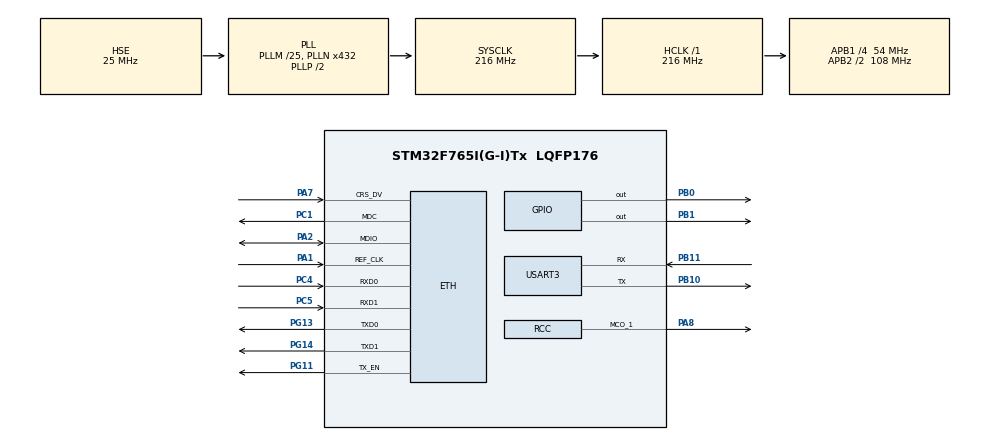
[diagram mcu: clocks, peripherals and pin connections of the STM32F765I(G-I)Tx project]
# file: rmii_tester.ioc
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ETH.MediaInterface=HAL_ETH_RMII_MODE
LWIP.BSP.number=1
LWIP.Version=v2.1.2_Cube
LWIP0.BSP.STBoard=false
LWIP0.BSP.api=BSP_COMPONENT_DRIVER
LWIP0.BSP.component=LAN8742
LWIP0.BSP.instance=LAN8742
LWIP0.BSP.name=Driver_PHY
LWIP0.BSP.semaphore=S_LAN8742
LWIP0.BSP.solution=LAN8742
Mcu.Family=STM32F7
Mcu.Name=STM32F765I(G-I)Tx
Mcu.Package=LQFP176
NVIC.PriorityGroup=NVIC_PRIORITYGROUP_4
PA1.Mode=RMII
PA1.Signal=ETH_REF_CLK
PA2.Mode=RMII
PA2.Signal=ETH_MDIO
PA7.Mode=RMII
PA7.Signal=ETH_CRS_DV
PA8.Mode=Clock-out-1
PA8.Signal=RCC_MCO_1
PB0.Signal=GPIO_Output
PB1.Signal=GPIO_Output
PB10.Mode=Asynchronous
PB10.Signal=USART3_TX
PB11.Mode=Asynchronous
PB11.Signal=USART3_RX
PC1.Mode=RMII
PC1.Signal=ETH_MDC
PC4.Mode=RMII
PC4.Signal=ETH_RXD0
PC5.Mode=RMII
PC5.Signal=ETH_RXD1
PG11.Mode=RMII
PG11.Signal=ETH_TX_EN
PG13.Mode=RMII
PG13.Signal=ETH_TXD0
PG14.Mode=RMII
PG14.Signal=ETH_TXD1
PH0/OSC_IN.Mode=HSE-External-Oscillator
PH0/OSC_IN.Signal=RCC_OSC_IN
PH1/OSC_OUT.Mode=HSE-External-Oscillator
PH1/OSC_OUT.Signal=RCC_OSC_OUT
ProjectManager.HeapSize=0x200
ProjectManager.StackSize=0x400
ProjectManager.TargetToolchain=Makefile
RCC.AHBFreq_Value=216000000
RCC.APB1CLKDivider=RCC_HCLK_DIV4
RCC.APB1Freq_Value=54000000
RCC.APB1TimFreq_Value=108000000
RCC.APB2CLKDivider=RCC_HCLK_DIV2
RCC.APB2Freq_Value=108000000
RCC.APB2TimFreq_Value=216000000
RCC.CortexFreq_Value=216000000
RCC.HCLKFreq_Value=216000000
RCC.HSE_VALUE=25000000
RCC.HSI_VALUE=16000000
RCC.LSE_VALUE=32768
RCC.PLLM=25
RCC.PLLN=432
RCC.PLLSourceVirtual=RCC_PLLSOURCE_HSE
RCC.RCC_MCO1Source=RCC_MCO1SOURCE_HSE
RCC.SYSCLKFreq_VALUE=216000000
RCC.SYSCLKSource=RCC_SYSCLKSOURCE_PLLCLK
RCC.USBFreq_Value=216000000
RCC.VCOOutputFreq_Value=432000000
USART3.VirtualMode-Asynchronous=VM_ASYNC
VP_LWIP_VS_Enabled.Mode=Enabled
board=custom

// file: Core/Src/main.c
/* USER CODE BEGIN Header */
/**
  ******************************************************************************
  * @file           : main.c
  * @brief          : Main program body
  ******************************************************************************
  * @attention
  *
  * Copyright (c) 2023 STMicroelectronics.
  * All rights reserved.
  *
  * This software is licensed under terms that can be found in the LICENSE file
  * in the root directory of this software component.
  * If no LICENSE file comes with this software, it is provided AS-IS.
  *
  ******************************************************************************
  */
/* USER CODE END Header */
#include "main.h"
#include "lwip.h"

UART_HandleTypeDef huart3;

void SystemClock_Config(void);
static void MX_GPIO_Init(void);
static void MX_USART3_UART_Init(void);

int main(void)
{

  /* MCU Configuration--------------------------------------------------------*/

  /* Reset of all peripherals, Initializes the Flash interface and the Systick. */
  HAL_Init();

  /* Configure the system clock */
  SystemClock_Config();

  /* Initialize all configured peripherals */
  MX_GPIO_Init();
  MX_USART3_UART_Init();
  HAL_GPIO_WritePin(GPIOB, GPIO_PIN_0|GPIO_PIN_1, GPIO_PIN_RESET);
  HAL_Delay(1);
  HAL_GPIO_WritePin(GPIOB, GPIO_PIN_0|GPIO_PIN_1, GPIO_PIN_SET);
  HAL_Delay(1);
  static const uint8_t msg[] = "Init LWIP...\r\n";
  HAL_UART_Transmit(&huart3, msg, sizeof(msg)-1, 1000000);
  MX_LWIP_Init();
  /* USER CODE BEGIN 2 */
  HAL_UART_Transmit(&huart3, "OK!\r\n", 5, 1000000);
  /* USER CODE END 2 */

  /* Infinite loop */
  while (1)
  {

    /* USER CODE BEGIN 3 */
    for (uint32_t t = HAL_GetTick(); HAL_GetTick()-t < 1000;) {
      MX_LWIP_Process();
    }
    if (dhcp_supplied_address(&gnetif)) {
      char buf[128];
      sprintf(buf, "Alive, DHCP-assigned IP = %s\r\n", ip4addr_ntoa(netif_ip4_addr(&gnetif)));
      HAL_UART_Transmit(&huart3, buf, strlen(buf), 1000000);
    } else {
      static const uint8_t msg[] = "Alive, no DHCP-assigned IP address\r\n";
      HAL_UART_Transmit(&huart3, msg, strlen(msg), 1000000);
    }
  }
  /* USER CODE END 3 */
}

void SystemClock_Config(void)
{
  RCC_OscInitTypeDef RCC_OscInitStruct = {0};
  RCC_ClkInitTypeDef RCC_ClkInitStruct = {0};

  /** Configure the main internal regulator output voltage
  */
  __HAL_RCC_PWR_CLK_ENABLE();
  __HAL_PWR_VOLTAGESCALING_CONFIG(PWR_REGULATOR_VOLTAGE_SCALE1);

  /** Initializes the RCC Oscillators according to the specified parameters
  * in the RCC_OscInitTypeDef structure.
  */
  RCC_OscInitStruct.OscillatorType = RCC_OSCILLATORTYPE_HSE;
  RCC_OscInitStruct.HSEState = RCC_HSE_ON;
  RCC_OscInitStruct.PLL.PLLState = RCC_PLL_ON;
  RCC_OscInitStruct.PLL.PLLSource = RCC_PLLSOURCE_HSE;
  RCC_OscInitStruct.PLL.PLLM = 25;
  RCC_OscInitStruct.PLL.PLLN = 432;
  RCC_OscInitStruct.PLL.PLLP = RCC_PLLP_DIV2;
  RCC_OscInitStruct.PLL.PLLQ = 2;
  RCC_OscInitStruct.PLL.PLLR = 2;
  if (HAL_RCC_OscConfig(&RCC_OscInitStruct) != HAL_OK)
  {
    Error_Handler();
  }

  /** Activate the Over-Drive mode
  */
  if (HAL_PWREx_EnableOverDrive() != HAL_OK)
  {
    Error_Handler();
  }

  /** Initializes the CPU, AHB and APB buses clocks
  */
  RCC_ClkInitStruct.ClockType = RCC_CLOCKTYPE_HCLK|RCC_CLOCKTYPE_SYSCLK
                              |RCC_CLOCKTYPE_PCLK1|RCC_CLOCKTYPE_PCLK2;
  RCC_ClkInitStruct.SYSCLKSource = RCC_SYSCLKSOURCE_PLLCLK;
  RCC_ClkInitStruct.AHBCLKDivider = RCC_SYSCLK_DIV1;
  RCC_ClkInitStruct.APB1CLKDivider = RCC_HCLK_DIV4;
  RCC_ClkInitStruct.APB2CLKDivider = RCC_HCLK_DIV2;

  if (HAL_RCC_ClockConfig(&RCC_ClkInitStruct, FLASH_LATENCY_7) != HAL_OK)
  {
    Error_Handler();
  }
  HAL_RCC_MCOConfig(RCC_MCO1, RCC_MCO1SOURCE_HSE, RCC_MCODIV_1);
}

static void MX_USART3_UART_Init(void)
{

  huart3.Instance = USART3;
  huart3.Init.BaudRate = 115200;
  huart3.Init.WordLength = UART_WORDLENGTH_8B;
  huart3.Init.StopBits = UART_STOPBITS_1;
  huart3.Init.Parity = UART_PARITY_NONE;
  huart3.Init.Mode = UART_MODE_TX_RX;
  huart3.Init.HwFlowCtl = UART_HWCONTROL_NONE;
  huart3.Init.OverSampling = UART_OVERSAMPLING_16;
  huart3.Init.OneBitSampling = UART_ONE_BIT_SAMPLE_DISABLE;
  huart3.AdvancedInit.AdvFeatureInit = UART_ADVFEATURE_NO_INIT;
  if (HAL_UART_Init(&huart3) != HAL_OK)
  {
    Error_Handler();
  }

}

static void MX_GPIO_Init(void)
{
  GPIO_InitTypeDef GPIO_InitStruct = {0};

  /* GPIO Ports Clock Enable */
  __HAL_RCC_GPIOH_CLK_ENABLE();
  __HAL_RCC_GPIOC_CLK_ENABLE();
  __HAL_RCC_GPIOA_CLK_ENABLE();
  __HAL_RCC_GPIOB_CLK_ENABLE();
  __HAL_RCC_GPIOG_CLK_ENABLE();

  /*Configure GPIO pin Output Level */
  HAL_GPIO_WritePin(GPIOB, GPIO_PIN_0|GPIO_PIN_1, GPIO_PIN_RESET);

  /*Configure GPIO pins : PB0 PB1 */
  GPIO_InitStruct.Pin = GPIO_PIN_0|GPIO_PIN_1;
  GPIO_InitStruct.Mode = GPIO_MODE_OUTPUT_PP;
  GPIO_InitStruct.Pull = GPIO_NOPULL;
  GPIO_InitStruct.Speed = GPIO_SPEED_FREQ_LOW;
  HAL_GPIO_Init(GPIOB, &GPIO_InitStruct);

  /*Configure GPIO pin : PA8 */
  GPIO_InitStruct.Pin = GPIO_PIN_8;
  GPIO_InitStruct.Mode = GPIO_MODE_AF_PP;
  GPIO_InitStruct.Pull = GPIO_NOPULL;
  GPIO_InitStruct.Speed = GPIO_SPEED_FREQ_LOW;
  GPIO_InitStruct.Alternate = GPIO_AF0_MCO;
  HAL_GPIO_Init(GPIOA, &GPIO_InitStruct);

}

void Error_Handler(void)
{
  __disable_irq();
  while (1)
  {
  }
}
